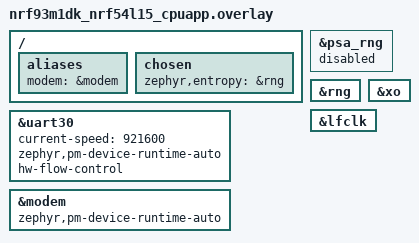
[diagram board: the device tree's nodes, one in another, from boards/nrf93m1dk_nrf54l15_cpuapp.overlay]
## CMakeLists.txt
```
# SPDX-License-Identifier: Apache-2.0

cmake_minimum_required(VERSION 3.20.0)

find_package(Zephyr REQUIRED HINTS $ENV{ZEPHYR_BASE})
project(lte_router)

# NORDIC SDK APP START
target_sources(app PRIVATE src/main.c)
# NORDIC SDK APP END
```

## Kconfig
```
# SPDX-License-Identifier: Apache-2.0
#
# Kconfig root for the lte_router application.

mainmenu "LTE Thread Border Router"

source "Kconfig.zephyr"
```

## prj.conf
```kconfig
CONFIG_EARLY_CONSOLE=y

# Generic networking options
CONFIG_NETWORKING=y
CONFIG_NET_NATIVE=y
CONFIG_NET_UDP=y
# No TCP: Thread/OT traffic is UDP/ICMP, DNS upstream forwarding is UDP,
# and the BR itself runs no cloud client.
CONFIG_NET_TCP=n
CONFIG_NET_IPV6=y
CONFIG_NET_IPV4=y
CONFIG_NET_IPV4_MAPPING_TO_IPV6=y
CONFIG_NET_SOCKETS=y
CONFIG_POSIX_API=y
CONFIG_NET_SOCKETS_INET_RAW=y
CONFIG_NET_MGMT=y
CONFIG_NET_MGMT_EVENT=y
CONFIG_NET_MGMT_EVENT_INFO=y
CONFIG_NET_CONNECTION_MANAGER=y
CONFIG_NET_SOCKETS_SERVICE=y
CONFIG_NET_CONTEXT_RECV_PKTINFO=y
CONFIG_NET_CONTEXT_RECV_HOPLIMIT=y
# 16 was enough with MAX_UDP_SERVICES=5; with 8 the socket service needs 17
# and refuses to start (net_sock_svc errors at boot, DNS/NAT64/SRP all fail).
CONFIG_ZVFS_POLL_MAX=20
CONFIG_NET_SOCKETS_SERVICE_STACK_SIZE=6144
CONFIG_NET_MAX_CONN=12
CONFIG_NET_CONNECTION_MANAGER_MONITOR_STACK_SIZE=1024

# printing of scan results puts pressure on queues in new locking
# design in net_mgmt. So, use a higher timeout for a crowded
# environment.
CONFIG_NET_MGMT_EVENT_QUEUE_TIMEOUT=5000
CONFIG_NET_MGMT_EVENT_QUEUE_SIZE=16

# PPP / LTE modem (nRF93M1 over uart30 + CMUX)
CONFIG_NET_L2_PPP=y
CONFIG_NET_L2_ETHERNET=n
CONFIG_MODEM=y
CONFIG_MODEM_CELLULAR=y
CONFIG_MODEM_MODULES=y
CONFIG_MODEM_CHAT=y
CONFIG_MODEM_BACKEND_UART=y
CONFIG_PM_DEVICE=y
CONFIG_PM_DEVICE_RUNTIME=y
CONFIG_PM_DEVICE_RUNTIME_USE_DEDICATED_WQ=y
CONFIG_PM_DEVICE_SHELL=y
CONFIG_MODEM_CELLULAR_USER_PIPE_BUFFER_SIZES=512
CONFIG_MODEM_AT_SHELL=y
CONFIG_MODEM_AT_USER_PIPE_IDX=0
# Required by MODEM_AT_SHELL
CONFIG_SHELL_WILDCARD=n
# Take DNS servers from IPCP negotiation (used by OT DNS upstream forwarding)
CONFIG_NET_L2_PPP_OPTION_DNS_USE=y

# DNS resolver required by DNS upstream resolver
CONFIG_DNS_RESOLVER=y
CONFIG_DNS_RESOLVER_PACKET_FORWARDING=y
CONFIG_DNS_RESOLVER_MAX_SERVERS=5
CONFIG_DNS_NUM_CONCUR_QUERIES=2
CONFIG_DNS_RESOLVER_MAX_NAME_LEN=128
CONFIG_DNS_RESOLVER_PRIVATE_RR_SUPPORT=y
CONFIG_DNS_RESOLVER_QUERY_ALL_AVAILABLE_SERVERS=y

# Generic OT options
CONFIG_NET_L2_OPENTHREAD=y
# Thread stack is started by the app calling openthread_run() after boot.
# NOTE: do NOT set this to n — auto-start then runs from net_if_up() during
# POST_KERNEL sysinit, before the OT platform/radio is ready, and the device
# dies silently before the boot banner (observed on-target).
CONFIG_OPENTHREAD_MANUAL_START=y
# Required dependency of NET_IPV6_FORWARDING (selected by the border router integration)
CONFIG_NET_IPV6_NBR_CACHE=y
CONFIG_NET_IPV6_ROUTE=y
CONFIG_OPENTHREAD_SHELL=y
CONFIG_OPENTHREAD_THREAD_VERSION_1_4=y
CONFIG_OPENTHREAD_ZEPHYR_BORDER_ROUTER=y
CONFIG_OPENTHREAD_FTD=y

# Thread network static dataset
CONFIG_OPENTHREAD_NETWORK_NAME="ot_lte_br"
CONFIG_OPENTHREAD_CHANNEL=11
CONFIG_OPENTHREAD_PANID=43981
CONFIG_OPENTHREAD_XPANID="de:ad:00:be:ef:00:ca:fe"
CONFIG_OPENTHREAD_NETWORKKEY="00:11:22:33:44:55:66:77:88:99:aa:bb:cc:dd:ee:ff"

# Kernel options
# 6144: boot-time secure-storage AEAD key derivation runs the deep CRACEN
# (sxsymcrypt) chain on the main stack once the storage partition holds data;
# 3072 overflowed and halted the board silently (see AGENTS.md).
CONFIG_MAIN_STACK_SIZE=6144
CONFIG_SHELL_STACK_SIZE=3072
CONFIG_OPENTHREAD_THREAD_STACK_SIZE=6144
CONFIG_LOG_PROCESS_THREAD_STACK_SIZE=1024
CONFIG_LOG_BUFFER_SIZE=1024
CONFIG_NET_TX_STACK_SIZE=2048
CONFIG_NET_RX_STACK_SIZE=2048
CONFIG_NET_MGMT_EVENT_STACK_SIZE=4096
CONFIG_SYSTEM_WORKQUEUE_STACK_SIZE=4096
CONFIG_ENTROPY_GENERATOR=y
CONFIG_TEST_RANDOM_GENERATOR=y
CONFIG_INIT_STACKS=y
CONFIG_STACK_SENTINEL=y

# OpenThread external heap (k_malloc based), sized to fit the 256K RAM of the nRF54L15
CONFIG_HEAP_MEM_POOL_SIZE=40960

# mbedTLS heap: crypto runs through PSA/CRACEN, only small mbedTLS allocs remain
CONFIG_MBEDTLS_HEAP_SIZE=2048

# 802.15.4 driver receive buffers (default 20)
CONFIG_NRF_802154_RX_BUFFERS=12

# Logging
# NOTE: for OpenThread stack logs set CONFIG_OPENTHREAD_DEBUG=y +
# CONFIG_OPENTHREAD_LOG_LEVEL_INFO=y (chatty; was used to diagnose SRP startup).
CONFIG_NET_LOG=y
CONFIG_LOG=y
CONFIG_LOG_PROCESS_THREAD=y
CONFIG_NET_STATISTICS=y
CONFIG_PRINTK=y
CONFIG_SHELL=y
CONFIG_NET_SHELL=y

# Network buffers (40+40 -> 32+32 to pay for the bigger main stack)
CONFIG_NET_PKT_RX_COUNT=14
CONFIG_NET_PKT_TX_COUNT=14
CONFIG_NET_BUF_RX_COUNT=32
CONFIG_NET_BUF_TX_COUNT=32
CONFIG_NET_BUF_DATA_SIZE=256
CONFIG_NET_MAX_CONTEXTS=12
CONFIG_NET_CONTEXT_NET_PKT_POOL=n

# IP address options
CONFIG_NET_IF_UNICAST_IPV6_ADDR_COUNT=6
CONFIG_NET_IF_MCAST_IPV6_ADDR_COUNT=6
CONFIG_NET_IF_MAX_IPV4_COUNT=2
CONFIG_NET_IF_MAX_IPV6_COUNT=6

# OT Border Router flags
# Default 5 is one too few: TMF + DNS-SD + Border Agent + mDNS/infra sockets
# already use all 5, and the SRP server's socket then fails with
# "Failed to prepare socket: InvalidState" (observed on-target).
CONFIG_OPENTHREAD_ZEPHYR_BORDER_ROUTER_MAX_UDP_SERVICES=8
# The bundled sdk-openthread fork has no otMdnsSetLocalHostName() API
CONFIG_OPENTHREAD_ZEPHYR_BORDER_ROUTER_MDNS_AUTO_NAMING=n
CONFIG_OPENTHREAD_SLAAC=y
CONFIG_OPENTHREAD_ENABLE_SERVICE=y
CONFIG_OPENTHREAD_BORDER_ROUTER=y
CONFIG_OPENTHREAD_BORDER_ROUTING=y
CONFIG_OPENTHREAD_BORDER_ROUTING_COUNTERS=y
CONFIG_OPENTHREAD_BORDER_AGENT=y
CONFIG_OPENTHREAD_BORDER_AGENT_ID=y
CONFIG_OPENTHREAD_NETDATA_PUBLISHER=y
CONFIG_OPENTHREAD_NAT64_TRANSLATOR=y
CONFIG_OPENTHREAD_DNSSD_SERVER=y
CONFIG_OPENTHREAD_EXTERNAL_HEAP=y
CONFIG_OPENTHREAD_JOINER=y
CONFIG_OPENTHREAD_COMMISSIONER=y
CONFIG_OPENTHREAD_PLATFORM_UDP=y
CONFIG_OPENTHREAD_MULTICAST_DNS=y
CONFIG_OPENTHREAD_MAX_STATECHANGE_HANDLERS=3
CONFIG_OPENTHREAD_INTERFACE_EARLY_UP=y
CONFIG_OPENTHREAD_ECDSA=y
CONFIG_OPENTHREAD_IP6_FRAGM=y
CONFIG_OPENTHREAD_COAP=y
CONFIG_OPENTHREAD_SETTINGS_RAM=y
CONFIG_OPENTHREAD_BORDER_AGENT_EPHEMERAL_KEY_ENABLE=y
CONFIG_OPENTHREAD_VERHOEFF_CHECKSUM=y
CONFIG_OPENTHREAD_BORDER_AGENT_MESHCOP_SERVICE=y
CONFIG_OPENTHREAD_DNS_UPSTREAM_QUERY=y
CONFIG_OPENTHREAD_SRP_CLIENT=y
CONFIG_OPENTHREAD_SRP_SERVER=y
CONFIG_OPENTHREAD_DUA=y
CONFIG_OPENTHREAD_MLR=y
CONFIG_OPENTHREAD_DNS_CLIENT=y
CONFIG_OPENTHREAD_PING_SENDER=y

# Disabled on purpose: no LAN behind an LTE PPP backbone
# (TREL, DHCPv6-PD, SRP advertising proxy, DNS-SD discovery proxy,
# backbone multicast routing stay off)

# PSA related
CONFIG_MBEDTLS_PSA_CRYPTO_LEGACY_RNG=y
```

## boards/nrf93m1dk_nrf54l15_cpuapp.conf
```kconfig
# Use UART async API with PM_RUNTIME.
CONFIG_UART_INTERRUPT_DRIVEN=n
CONFIG_UART_ASYNC_API=y
CONFIG_SHELL_BACKEND_SERIAL_API_ASYNC=y
CONFIG_MODEM_BACKEND_UART_ASYNC_HWFC=y
CONFIG_MODEM_BACKEND_UART_ASYNC_RECEIVE_IDLE_TIMEOUT_MS=1

CONFIG_MODEM_CMUX_MTU=127
CONFIG_MODEM_CMUX_WORK_BUFFER_SIZE_EXTRA=532
CONFIG_MODEM_CELLULAR_UART_BUFFER_SIZES=532
CONFIG_MODEM_CMUX_MSC_FC_THRESHOLD=32

# Carrier APN (simbase SIM)
CONFIG_MODEM_CELLULAR_APN="simbase"
```

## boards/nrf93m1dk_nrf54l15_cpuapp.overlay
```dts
/ {
	aliases {
		modem = &modem;
	};

	chosen {
		zephyr,entropy = &rng;
	};
};

&uart30 {
	status = "okay";
	/* 921600 requires the modem's +IPR to be programmed to 921600 once
	 * (stored in modem NVM) BEFORE flashing this — see AGENTS.md.
	 * HW flow control is mandatory above 115200. */
	current-speed = <921600>;
	zephyr,pm-device-runtime-auto;
	hw-flow-control;
};

&modem {
	status = "okay";
	zephyr,pm-device-runtime-auto;
};

&psa_rng {
	status = "disabled";
};

&rng {
	status = "okay";
};

&xo {
	status = "okay";
};

&lfclk {
	status = "okay";
};
```

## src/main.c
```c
/*
 * Copyright 2026
 *
 * SPDX-License-Identifier: Apache-2.0
 */

#include <zephyr/kernel.h>
#include <zephyr/drivers/gpio.h>
#include <zephyr/logging/log.h>
#include <zephyr/net/net_event.h>
#include <zephyr/net/net_if.h>
#include <zephyr/net/net_mgmt.h>
#include <zephyr/net/ppp.h>
#include <openthread.h>
#include <openthread/thread.h>

LOG_MODULE_REGISTER(main, LOG_LEVEL_INF);

static const struct gpio_dt_spec led = GPIO_DT_SPEC_GET(DT_ALIAS(led2), gpios);

static struct net_mgmt_event_callback net_cb;

static const char *iface_l2_name(struct net_if *iface)
{
	if (net_if_l2(iface) == &NET_L2_GET_NAME(PPP)) {
		return "PPP";
	}

	return "other";
}

static void net_event_handler(struct net_mgmt_event_callback *cb, uint64_t mgmt_event,
			      struct net_if *iface)
{
	ARG_UNUSED(cb);

	switch (mgmt_event) {
	case NET_EVENT_IF_UP:
		LOG_INF("iface %d (%s) UP", net_if_get_by_iface(iface), iface_l2_name(iface));
		break;
	case NET_EVENT_IF_DOWN:
		LOG_INF("iface %d (%s) DOWN", net_if_get_by_iface(iface), iface_l2_name(iface));
		break;
	case NET_EVENT_IPV4_ADDR_ADD:
		LOG_INF("iface %d (%s) IPv4 address added", net_if_get_by_iface(iface),
			iface_l2_name(iface));
		break;
	case NET_EVENT_L4_CONNECTED:
		LOG_INF("L4 connected");
		break;
	case NET_EVENT_L4_DISCONNECTED:
		LOG_INF("L4 disconnected");
		break;
	default:
		break;
	}
}

static bool thread_started;

/*
 * OpenThread API calls (ifconfig up + thread start) are deep and do not fit
 * the main stack — calling openthread_run() directly from main() overflowed
 * it and the PSPLIM guard halted the system (observed on-target).
 * The system workqueue has a 4096-byte stack, like the OT shell path.
 */
static void start_thread_work_handler(struct k_work *work)
{
	int err;

	ARG_UNUSED(work);

	if (thread_started) {
		return;
	}

	err = openthread_run();
	if (err != 0) {
		LOG_ERR("Failed to start OpenThread (%d)", err);
		return;
	}

	thread_started = true;
}

static K_WORK_DEFINE(start_thread_work, start_thread_work_handler);

int main(void)
{
	struct net_if *ppp_iface;

	if (gpio_is_ready_dt(&led)) {
		(void)gpio_pin_configure_dt(&led, GPIO_OUTPUT_INACTIVE);
	}

	net_mgmt_init_event_callback(&net_cb, net_event_handler,
				     NET_EVENT_IF_UP | NET_EVENT_IF_DOWN |
				     NET_EVENT_IPV4_ADDR_ADD |
				     NET_EVENT_L4_CONNECTED | NET_EVENT_L4_DISCONNECTED);
	net_mgmt_add_event_callback(&net_cb);

	/* Do not use net_if_get_by_index() here: the OpenThread interface shifts indices. */
	ppp_iface = net_if_get_first_by_type(&NET_L2_GET_NAME(PPP));
	if (ppp_iface == NULL) {
		LOG_ERR("PPP interface not found");
	} else if (!net_if_is_up(ppp_iface)) {
		LOG_INF("Bringing up PPP interface %d", net_if_get_by_iface(ppp_iface));
		(void)net_if_up(ppp_iface);
	}

	/*
	 * Start the Thread stack only once the LTE backbone has its IPv4
	 * address: the border router must see a ready AIL when Thread starts,
	 * otherwise it never publishes the on-mesh and NAT64 prefixes to
	 * network data (observed on-target). Poll once a second instead of
	 * relying on net_mgmt events. Thread is started from the system
	 * workqueue because openthread_run() is too deep for the main stack.
	 */
	while (true) {
		if (!thread_started && ppp_iface != NULL) {
			struct net_in_addr *ipv4_addr;

			ipv4_addr = net_if_ipv4_get_global_addr(ppp_iface, NET_ADDR_PREFERRED);
			if (ipv4_addr != NULL) {
				/*
				 * PPP is point-to-point and the peer hands us no
				 * gateway, but without a default route the IPv4 route
				 * lookup used by the NAT64 raw-socket egress fails
				 * (default iface is thread0). Use our own address as
				 * the dummy gateway and make PPP the default interface.
				 */
				net_if_ipv4_set_gw(ppp_iface, ipv4_addr);
				net_if_set_default(ppp_iface);
				LOG_INF("PPP IPv4 up, default route set, starting Thread");
				k_work_submit(&start_thread_work);
			}
		}

		if (gpio_is_ready_dt(&led)) {
			(void)gpio_pin_toggle_dt(&led);
		}
		k_sleep(K_SECONDS(1));
	}

	return 0;
}
```
